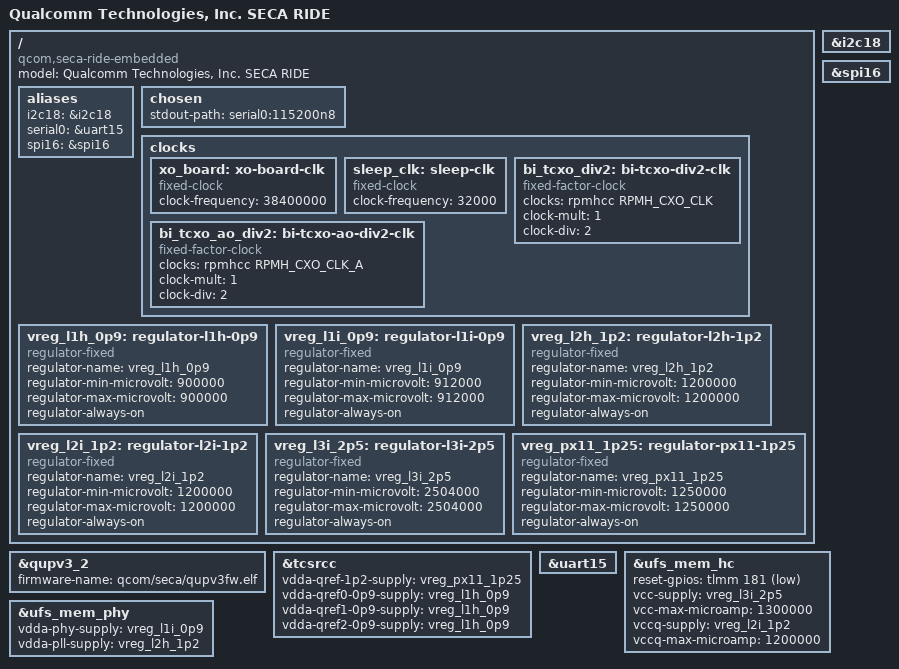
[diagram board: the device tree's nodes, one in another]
// SPDX-License-Identifier: BSD-3-Clause
/*
 * Copyright (c) Qualcomm Technologies, Inc. and/or its subsidiaries.
 */

/dts-v1/;

#include <dt-bindings/gpio/gpio.h>

#include "seca-embedded.dtsi"

/ {
	model = "Qualcomm Technologies, Inc. SECA RIDE";
	compatible = "qcom,seca-ride-embedded", "qcom,seca";

	aliases {
		i2c18 = &i2c18;
		serial0 = &uart15;
		spi16 = &spi16;
	};

	chosen {
		stdout-path = "serial0:115200n8";
	};

	clocks {
		xo_board: xo-board-clk {
			compatible = "fixed-clock";
			clock-frequency = <38400000>;
			#clock-cells = <0>;
		};

		sleep_clk: sleep-clk {
			compatible = "fixed-clock";
			clock-frequency = <32000>;
			#clock-cells = <0>;
		};

		bi_tcxo_div2: bi-tcxo-div2-clk {
			compatible = "fixed-factor-clock";
			#clock-cells = <0>;
			clocks = <&rpmhcc RPMH_CXO_CLK>;
			clock-mult = <1>;
			clock-div = <2>;
		};

		bi_tcxo_ao_div2: bi-tcxo-ao-div2-clk {
			compatible = "fixed-factor-clock";
			#clock-cells = <0>;
			clocks = <&rpmhcc RPMH_CXO_CLK_A>;
			clock-mult = <1>;
			clock-div = <2>;
		};
	};

	/*
	 * The boot firmware owns these PMIC rails: cmd-db offers no PMIC LDO
	 * resources to the application processor on this platform.
	 */
	vreg_l1h_0p9: regulator-l1h-0p9 {
		compatible = "regulator-fixed";
		regulator-name = "vreg_l1h_0p9";
		regulator-min-microvolt = <900000>;
		regulator-max-microvolt = <900000>;
		regulator-always-on;
	};

	vreg_l1i_0p9: regulator-l1i-0p9 {
		compatible = "regulator-fixed";
		regulator-name = "vreg_l1i_0p9";
		regulator-min-microvolt = <912000>;
		regulator-max-microvolt = <912000>;
		regulator-always-on;
	};

	vreg_l2h_1p2: regulator-l2h-1p2 {
		compatible = "regulator-fixed";
		regulator-name = "vreg_l2h_1p2";
		regulator-min-microvolt = <1200000>;
		regulator-max-microvolt = <1200000>;
		regulator-always-on;
	};

	vreg_l2i_1p2: regulator-l2i-1p2 {
		compatible = "regulator-fixed";
		regulator-name = "vreg_l2i_1p2";
		regulator-min-microvolt = <1200000>;
		regulator-max-microvolt = <1200000>;
		regulator-always-on;
	};

	vreg_l3i_2p5: regulator-l3i-2p5 {
		compatible = "regulator-fixed";
		regulator-name = "vreg_l3i_2p5";
		regulator-min-microvolt = <2504000>;
		regulator-max-microvolt = <2504000>;
		regulator-always-on;
	};

	vreg_px11_1p25: regulator-px11-1p25 {
		compatible = "regulator-fixed";
		regulator-name = "vreg_px11_1p25";
		regulator-min-microvolt = <1250000>;
		regulator-max-microvolt = <1250000>;
		regulator-always-on;
	};
};

&i2c18 {
	status = "okay";
};

&qupv3_2 {
	firmware-name = "qcom/seca/qupv3fw.elf";

	status = "okay";
};

&spi16 {
	status = "okay";
};

&tcsrcc {
	vdda-qref-1p2-supply = <&vreg_px11_1p25>;
	vdda-qref0-0p9-supply = <&vreg_l1h_0p9>;
	vdda-qref1-0p9-supply = <&vreg_l1h_0p9>;
	vdda-qref2-0p9-supply = <&vreg_l1h_0p9>;
};

&uart15 {
	status = "okay";
};

&ufs_mem_hc {
	reset-gpios = <&tlmm 181 GPIO_ACTIVE_LOW>;

	vcc-supply = <&vreg_l3i_2p5>;
	vcc-max-microamp = <1300000>;
	vccq-supply = <&vreg_l2i_1p2>;
	vccq-max-microamp = <1200000>;

	status = "okay";
};

&ufs_mem_phy {
	vdda-phy-supply = <&vreg_l1i_0p9>;
	vdda-pll-supply = <&vreg_l2h_1p2>;

	status = "okay";
};
